# GD32F30x_XD register map
File version: 1.0
CPU: CM4 r2p1, little endian, MPU, FPU, 4 interrupt priority bits
Registers are 32-bit, read-write, reset 0x0 unless marked. A register's access mark holds for its fields unless they carry their own. Offsets are from the block's base; [hi:lo] are bit positions; {n}, {i} and the like mark numbered series; 'fields as' and 'values as' point back to an identical list.

## EXTI — External interrupt/event controller
Base 0x40010400
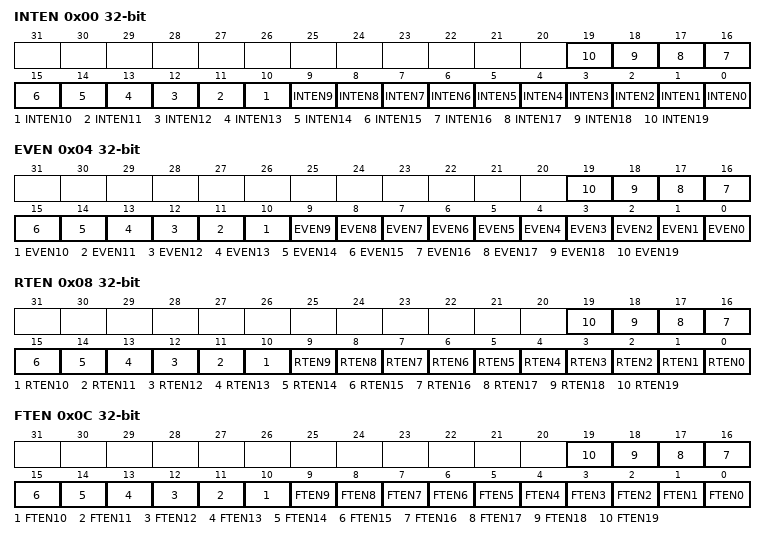
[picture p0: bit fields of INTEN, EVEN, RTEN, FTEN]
0x00 INTEN — Interrupt enable register (EXTI_INTEN)
  [n] INTEN{n} (n=0..19) — Enable Interrupt on line {n}
0x04 EVEN — Event enable register (EXTI_EVEN)
  [n] EVEN{n} (n=0..19) — Enable Event on line {n}
0x08 RTEN — Rising Edge Trigger Enable register (EXTI_RTEN)
  [n] RTEN{n} (n=0..19) — Rising edge trigger enable of line {n}
0x0C FTEN — Falling Egde Trigger Enable register (EXTI_FTEN)
  [n] FTEN{n} (n=0..19) — Falling edge trigger enable of line {n}
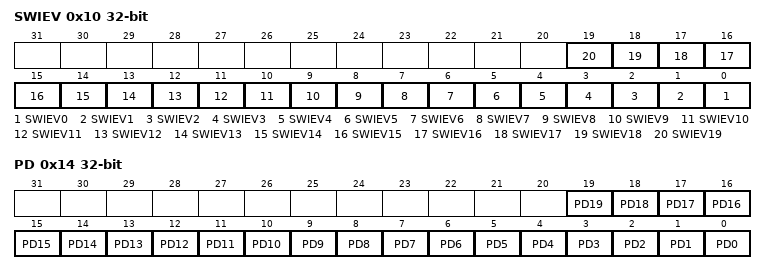
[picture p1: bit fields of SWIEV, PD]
0x10 SWIEV — Software interrupt event register (EXTI_SWIEV)
  [n] SWIEV{n} (n=0..19) — Interrupt/Event software trigger on line {n}
0x14 PD — Pending register (EXTI_PD)
  [n] PD{n} (n=0..19) — Interrupt pending status of line {n}

## FMC
Base 0x40022000
0x00 WS — wait state counter register
  [2:0] WSCNT
0x04 KEY wo — Unlock key register
  [31:0] KEY — FMC_CTL unlock register
0x08 OBKEY wo — Option byte unlock key register
  [31:0] OBKEY — FMC_ OBCTL0 option byte operation unlock register
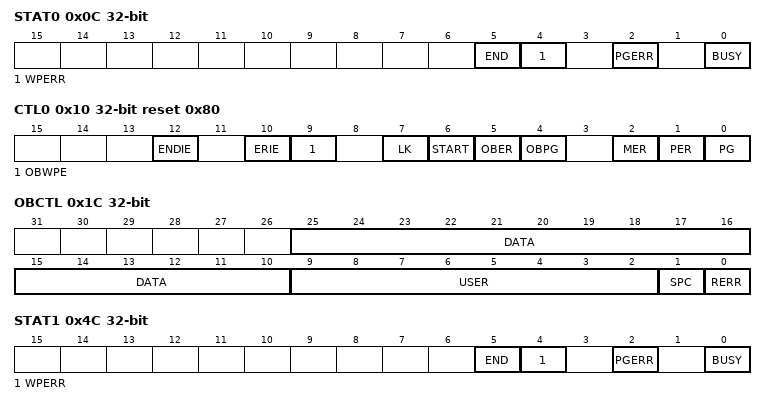
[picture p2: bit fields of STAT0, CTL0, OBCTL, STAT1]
0x0C STAT0 access per field — Status register 0
  [5] END rw — End of operation flag bit
  [4] WPERR rw — Erase/Program protection error flag bit
  [2] PGERR rw — Program error flag bit
  [0] BUSY ro — The flash is busy bit
0x10 CTL0 reset 0x80 — Control register 0
  [12] ENDIE — End of operation interrupt enable bit
  [10] ERIE — Error interrupt enable bit
  [9] OBWPE — Option byte erase/program enable bit
  [7] LK — FMC_CTL0 lock bit
  [6] START — Send erase command to FMC bit
  [5] OBER — Option bytes erase command bit
  [4] OBPG — Option bytes program command bit
  [2] MER — Main flash mass erase for bank0 command bit
  [1] PER — Main flash page erase for bank0 command bit
  [0] PG — Main flash program for bank0 command bit
0x14 ADDR0 wo — Address register 0
  [31:0] ADDR — Flash erase/program command address bits
0x1C OBCTL ro — Option byte control register
  [25:10] DATA — Store DATA[15:0] of option bytes block after system reset
  [9:2] USER — Store USER of option bytes block after system reset
  [1] SPC — Option bytes security protection code
  [0] RERR — Option bytes read error bit
0x20 WPR ro — Erase/Program Protection register
  [31:0] WP — Store WP[31:0] of option bytes block after system reset
0x44 KEY1 wo — Unlock key register 1
  [31:0] KEY — FMC_CTL unlock register
0x4C STAT1 access per field — Status register 1
  fields as STAT0
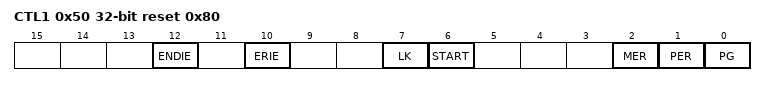
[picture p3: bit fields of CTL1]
0x50 CTL1 reset 0x80 — Control register 1
  [12] ENDIE — End of operation interrupt enable bit
  [10] ERIE — Error interrupt enable bit
  [7] LK — FMC_CTL0 lock bit
  [6] START — Send erase command to FMC bit
  [2] MER — Main flash mass erase for bank0 command bit
  [1] PER — Main flash page erase for bank0 command bit
  [0] PG — Main flash program for bank0 command bit
0x54 ADDR1 wo — Address register 1
  [31:0] ADDR — Flash erase/program command address bits
0xFC WSEN — Wait state enable register
  [0] WSEN — FMC wait state enable register
0x100 PID ro — Product ID register
  [31:0] PID — Product reserved ID code register

## FWDGT — free watchdog timer
Base 0x40003000
0x00 CTL wo — Control register
  [15:0] CMD — Key value
0x04 PSC — Prescaler register
  [2:0] PSC — Free watchdog timer prescaler selection
0x08 RLD reset 0xFFF — Reload register
  [11:0] RLD — Free watchdog timer counter reload value
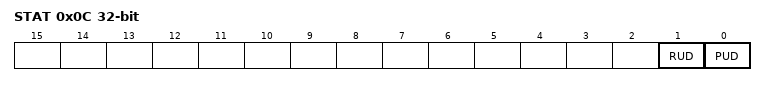
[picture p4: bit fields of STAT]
0x0C STAT ro — Status register
  [1] RUD — Free watchdog timer counter reload value update
  [0] PUD — Free watchdog timer prescaler value update

## GPIOA — General-purpose I/Os
Base 0x40010800
Same registers: GPIOB 0x40010C00, GPIOC 0x40011000, GPIOD 0x40011400, GPIOE 0x40011800, GPIOF 0x40011C00, GPIOG 0x40012000
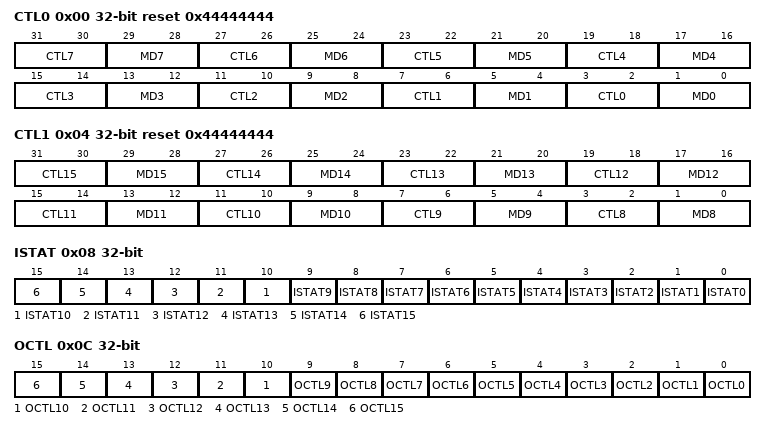
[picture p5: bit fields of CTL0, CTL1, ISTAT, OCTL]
0x00 CTL0 reset 0x44444444 — port control register 0
  [4n+3:4n+2] CTL{n} (n=0..7) — Port x configuration bits (x = {n})
  [4n+1:4n] MD{n} (n=4..7) — Port x mode bits (x = {n})
  [13:12] MD3 — Port x mode bits (x = 3 )
  [9:8] MD2 — Port x mode bits (x = 2 )
  [5:4] MD1 — Port x mode bits (x = 1)
  [1:0] MD0 — Port x mode bits (x = 0)
0x04 CTL1 reset 0x44444444 — port control register 1
  [4n-29:4n-30] CTL{n} (n=8..15) — Port x configuration bits (x = {n})
  [4n-31:4n-32] MD{n} (n=12..15) — Port x mode bits (x = {n})
  [13:12] MD11 — Port x mode bits (x = 11 )
  [9:8] MD10 — Port x mode bits (x = 10 )
  [5:4] MD9 — Port x mode bits (x = 9)
  [1:0] MD8 — Port x mode bits (x = 8)
0x08 ISTAT ro — Port input status register
  [n] ISTAT{n} (n=0..15) — Port input status
0x0C OCTL — Port output control register
  [n] OCTL{n} (n=0..15) — Port output control
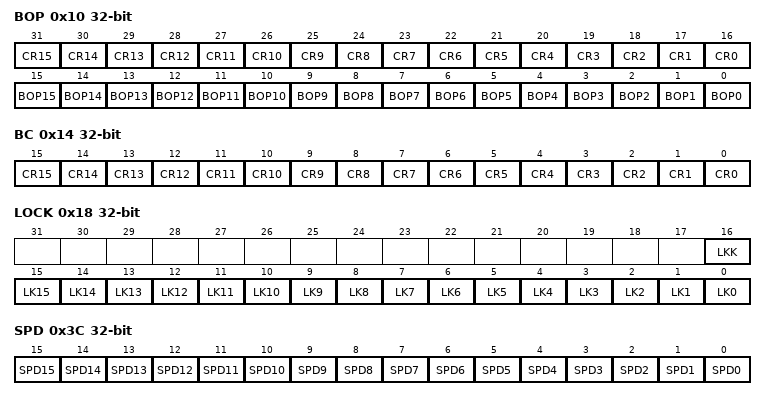
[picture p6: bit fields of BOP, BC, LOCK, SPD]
0x10 BOP wo — Port bit operate register
  [n+16] CR{n} (n=0..15) — Port {n} Clear bit
  [n] BOP{n} (n=0..15) — Port {n} Set bit
0x14 BC wo — Port bit clear register
  [n] CR{n} (n=0..15) — Port {n} Clear bit
0x18 LOCK — GPIO port configuration lock register
  [16] LKK — Lock sequence key
  [n] LK{n} (n=0..15) — Port Lock bit {n}
0x3C SPD — Port bit speed register
  [n] SPD{n} (n=0..15) — Port {n} output max speed bits
